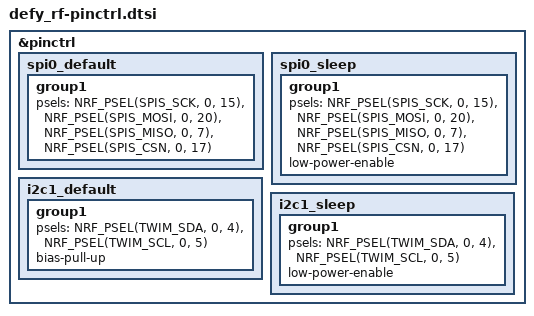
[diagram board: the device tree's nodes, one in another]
/*
 * SPDX-License-Identifier: MIT
 */

&pinctrl {
    /* SPIS pins as the stock radio firmware selects them. */
    spi0_default: spi0_default {
        group1 {
            psels = <NRF_PSEL(SPIS_SCK, 0, 15)>,
                    <NRF_PSEL(SPIS_MOSI, 0, 20)>,
                    <NRF_PSEL(SPIS_MISO, 0, 7)>,
                    <NRF_PSEL(SPIS_CSN, 0, 17)>;
        };
    };

    spi0_sleep: spi0_sleep {
        group1 {
            psels = <NRF_PSEL(SPIS_SCK, 0, 15)>,
                    <NRF_PSEL(SPIS_MOSI, 0, 20)>,
                    <NRF_PSEL(SPIS_MISO, 0, 7)>,
                    <NRF_PSEL(SPIS_CSN, 0, 17)>;
            low-power-enable;
        };
    };

    /* Battery gauge and charger. */
    i2c1_default: i2c1_default {
        group1 {
            psels = <NRF_PSEL(TWIM_SDA, 0, 4)>,
                    <NRF_PSEL(TWIM_SCL, 0, 5)>;
            bias-pull-up;
        };
    };

    i2c1_sleep: i2c1_sleep {
        group1 {
            psels = <NRF_PSEL(TWIM_SDA, 0, 4)>,
                    <NRF_PSEL(TWIM_SCL, 0, 5)>;
            low-power-enable;
        };
    };
};
